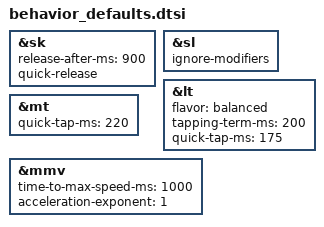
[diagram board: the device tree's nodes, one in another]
/* default settings overrides */

&sk {
  release-after-ms = <900>;
  quick-release;
};

&sl { // Allow sticky mods to chord across sticky layers.
  ignore-modifiers;
};

&lt {
    flavor = "balanced";
    tapping-term-ms = <200>;
    quick-tap-ms = <175>;
};

&mt {
    quick-tap-ms = <220>;
};

&mmv {
    time-to-max-speed-ms = <1000>;
    acceleration-exponent = <1>;
};
